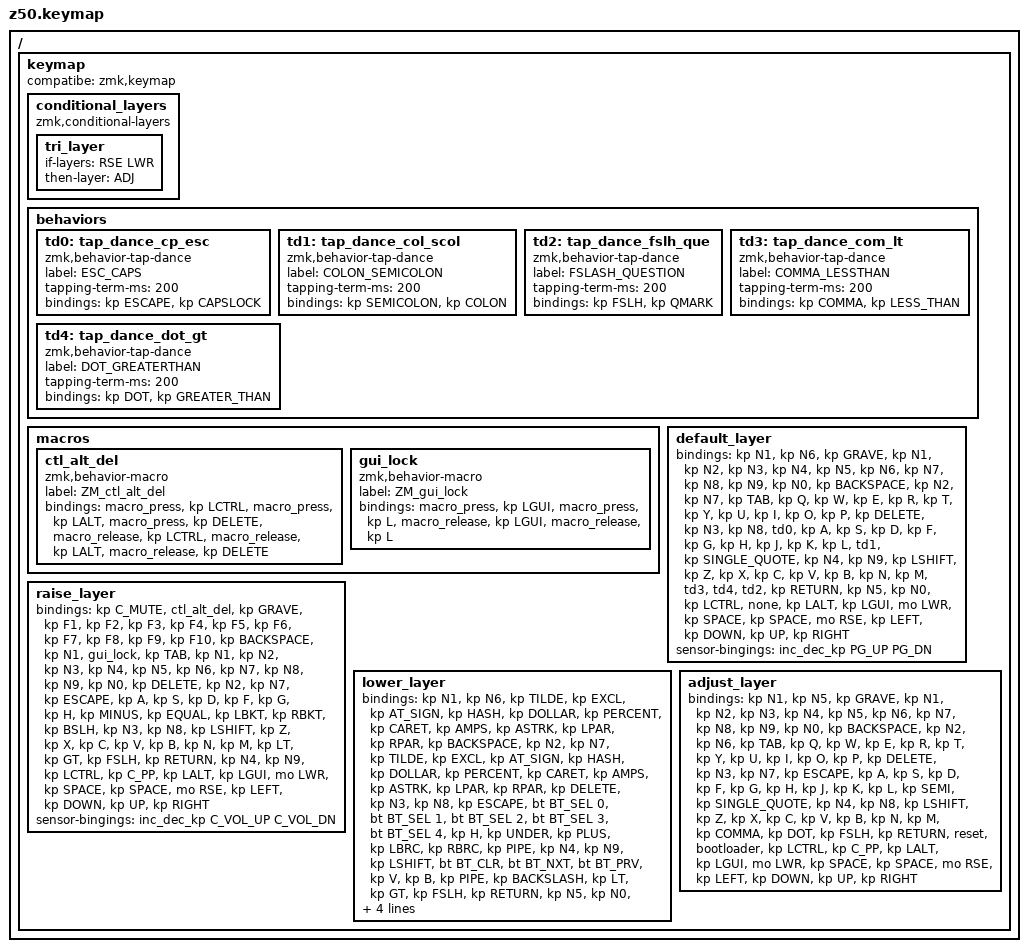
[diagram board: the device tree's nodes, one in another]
#include <behaviors.dtsi>
#include <dt-bindings/zmk/keys.h>
#include <dt-bindings/zmk/bt.h>

#define DEFAULT 0
#define RSE 1
#define LWR 2
#define ADJ 3

/ {
    keymap {
        compatibe = "zmk,keymap";
        // Trigger Adjust layer
        conditional_layers {
            compatible = "zmk,conditional-layers";
            tri_layer {
                if-layers = <RSE LWR>;
                then-layer = <ADJ>;
            };
        };
        // Tap dance behaviors
        behaviors {
            // <ESC, CAPSLOCK>
            td0: tap_dance_cp_esc {
                compatible = "zmk,behavior-tap-dance";
                label = "ESC_CAPS";
                #binding-cells = <0>;
                tapping-term-ms = <200>;
                bindings = <&kp ESCAPE>, <&kp CAPSLOCK>;
            };
            // <SEMICOLON, COLON>
            td1: tap_dance_col_scol {
                compatible = "zmk,behavior-tap-dance";
                label = "COLON_SEMICOLON";
                #binding-cells = <0>;
                tapping-term-ms = <200>;
                bindings = <&kp SEMICOLON>, <&kp COLON>;
            };
            // <FORWARDSLASH, QUESTION>
            td2: tap_dance_fslh_que {
                compatible = "zmk,behavior-tap-dance";
                label = "FSLASH_QUESTION";
                #binding-cells = <0>;
                tapping-term-ms = <200>;
                bindings = <&kp FSLH>, <&kp QMARK>;
            };
            // <COMMA, LESSTHAN>
            td3: tap_dance_com_lt {
                compatible = "zmk,behavior-tap-dance";
                label = "COMMA_LESSTHAN";
                #binding-cells = <0>;
                tapping-term-ms = <200>;
                bindings = <&kp COMMA>, <&kp LESS_THAN>;
            };
            // <PERIOD, GREATERTHAN>
            td4: tap_dance_dot_gt {
                compatible = "zmk,behavior-tap-dance";
                label = "DOT_GREATERTHAN";
                #binding-cells = <0>;
                tapping-term-ms = <200>;
                bindings = <&kp DOT>, <&kp GREATER_THAN>;
            };
        };
        // Macros
        macros {
            ctl_alt_del: ctl_alt_del {
                label = "ZM_ctl_alt_del";
                compatible = "zmk,behavior-macro";
                #binding-cells = <0>;
                bindings = <&macro_press &kp LCTRL>,
                    <&macro_press &kp LALT>,
                    <&macro_press &kp DELETE>,
                    <&macro_release &kp LCTRL>,
                    <&macro_release &kp LALT>,
                    <&macro_release &kp DELETE>;
            };
            gui_lock: gui_lock {
                label = "ZM_gui_lock";
                compatible = "zmk,behavior-macro";
                #binding-cells = <0>;
                bindings = <&macro_press &kp LGUI>,
                    <&macro_press &kp L>,
                    <&macro_release &kp LGUI>,
                    <&macro_release &kp L>;
            };
        };
        // Keymaps by layer
        default_layer {
        // +-----------+----------+---------+-------+-------+-------+-------+-------+-------+-------+-------+-------+-------+---------+
        // |    ENC    |   MC 5   |    `    |   1   |   2   |   3   |   4   |   5   |   6   |   7   |   8   |   9   |   0   |  BKSPC  |   
        // +-----------+----------+---------+-------+-------+-------+-------+-------+-------+-------+-------+-------+-------+---------+
        // |    MC 1   |   MC 6   |   TAB   |   Q   |   W   |   E   |   R   |   T   |   Y   |   U   |   I   |   O   |   P   |   DEL   |
        // +-----------+----------+---------+-------+-------+-------+-------+-------+-------+-------+-------+-------+-------+---------+
        // |    MC 2   |   MC 7   |   ESC   |   A   |   S   |   D   |   F   |   G   |   H   |   J   |   K   |   L   |   ;   |    '    |       
        // +-----------+----------+---------+-------+-------+-------+-------+-------+-------+-------+-------+-------+-------+---------+
        // |    MC 3   |   MC 8   |  SHIFT  |   Z   |   X   |   C   |   V   |   B   |   N   |   M   |   ,   |   .   |   /   |  RETURN |   
        // +-----------+----------+---------+-------+-------+-------+-------+-------+-------+-------+-------+-------+-------+---------+
        // |    MC 4   |   MC 9   |   CTRL  |  FN   | LALT  |  GUI  |  LWR  | SPACE | SPACE |  RSE  | LEFT  | DOWN  |   UP  |  RIGHT  |    
        // +-----------+----------+---------+-------+-------+-------+-------+-------+-------+-------+-------+-------+-------+---------+
            bindings = <
                &kp N1   &kp N6   &kp GRAVE   &kp N1  &kp N2   &kp N3   &kp N4    &kp N5    &kp N6    &kp N7   &kp N8    &kp N9   &kp N0    &kp BACKSPACE 
                &kp N2   &kp N7   &kp TAB     &kp Q   &kp W    &kp E    &kp R     &kp T     &kp Y     &kp U    &kp I     &kp O    &kp P     &kp DELETE
                &kp N3   &kp N8   &td0  &kp A   &kp S    &kp D    &kp F     &kp G     &kp H     &kp J    &kp K     &kp L    &td1  &kp SINGLE_QUOTE
                &kp N4   &kp N9   &kp LSHIFT  &kp Z   &kp X    &kp C    &kp V     &kp B     &kp N     &kp M    &td3 &td4  &td2  &kp RETURN
                &kp N5   &kp N0   &kp LCTRL   &none   &kp LALT &kp LGUI &mo LWR   &kp SPACE &kp SPACE &mo RSE  &kp LEFT  &kp DOWN &kp UP    &kp RIGHT
            >;
            sensor-bingings = <&inc_dec_kp PG_UP PG_DN>;
        };
        
        raise_layer {
        // ENC = C_MUTE
        // MC 5 = CTL+ALT+DEL -- login to windows 
        // MC 6 = LGUI+L -- lock windows desktop
        // +-----------+----------+---------+-------+-------+-------+-------+-------+-------+-------+---------+---------+--------+---------+
        // |    ENC    |   MC 5   |    `    |   F1  |   F2  |   F3  |   F4  |   F5  |   F6  |   F7  |   F8    |   F9    |   F10  |  BKSPC  |   
        // +-----------+----------+---------+-------+-------+-------+-------+-------+-------+-------+---------+---------+--------+---------+
        // |    MC 1   |   MC 6   |   TAB   |   1   |   2   |   3   |   4   |   5   |   6   |   7   |   8     |   9     |    0   |   DEL   |
        // +-----------+----------+---------+-------+-------+-------+-------+-------+-------+-------+---------+---------+--------+---------+
        // |    MC 2   |   MC 7   |   ESC   |   A   |   S   |   D   |   F   |   G   |   H   |   -   |   =     |   [     |   ]    |    \    |       
        // +-----------+----------+---------+-------+-------+-------+-------+-------+-------+-------+---------+---------+--------+---------+
        // |    MC 3   |   MC 8   |  SHIFT  |   Z   |   X   |   C   |   V   |   B   |   N   |   M   |   <     |   >     |   /    |  RETURN |   
        // +-----------+----------+---------+-------+-------+-------+-------+-------+-------+-------+---------+---------+--------+---------+
        // |    MC 4   |   MC 9   |   CTRL  |  FN   | LALT  |  GUI  |  LWR  | SPACE | SPACE |  RSE  | OUT_USB | OUT_BLE |  RALT  | OUT_TOG |    
        // +-----------+----------+---------+-------+-------+-------+-------+-------+-------+-------+---------+---------+--------+---------+
            bindings = <
                &kp C_MUTE   &ctl_alt_del   &kp GRAVE   &kp F1  &kp F2   &kp F3   &kp F4    &kp F5    &kp F6    &kp F7   &kp F8    &kp F9   &kp F10    &kp BACKSPACE 
                &kp N1   &gui_lock   &kp TAB     &kp N1   &kp N2    &kp N3    &kp N4    &kp N5     &kp N6     &kp N7    &kp N8     &kp N9    &kp N0     &kp DELETE
                &kp N2   &kp N7   &kp ESCAPE  &kp A   &kp S    &kp D    &kp F     &kp G     &kp H     &kp MINUS    &kp EQUAL     &kp LBKT    &kp RBKT  &kp BSLH
                &kp N3   &kp N8   &kp LSHIFT  &kp Z   &kp X    &kp C    &kp V     &kp B     &kp N     &kp M    &kp LT &kp GT  &kp FSLH  &kp RETURN
                &kp N4   &kp N9   &kp LCTRL   &kp C_PP  &kp LALT &kp LGUI &mo LWR   &kp SPACE &kp SPACE &mo RSE  &kp LEFT  &kp DOWN &kp UP    &kp RIGHT
            >;
            sensor-bingings = <&inc_dec_kp C_VOL_UP C_VOL_DN>;
        };

        lower_layer {
        // +-----------+----------+---------+--------+--------+--------+-------+-------+-------+-------+-------+-------+-------+---------+
        // |    ENC    |   MC 5   |    ~    |    !   |   @    |    #   |   $   |   %   |   ^   |   &   |   *   |   (   |   )   |  BKSPC  |   
        // +-----------+----------+---------+--------+--------+--------+-------+-------+-------+-------+-------+-------+-------+---------+
        // |    MC 1   |   MC 6   |   TAB   |    !   |   @    |    #   |   $   |   %   |   ^   |   &   |   *   |   (   |   )   |   DEL   |
        // +-----------+----------+---------+--------+--------+--------+-------+-------+-------+-------+-------+-------+-------+---------+
        // |    MC 2   |   MC 7   |   ESC   |  BT 1  |  BT 2  |  BT 3  | BT 4  | BT 5  |   H   |   _   |   +   |   {   |   }   |    |    |       
        // +-----------+----------+---------+--------+--------+--------+-------+-------+-------+-------+-------+-------+-------+---------+
        // |    MC 3   |   MC 8   |  SHIFT  | BT_CLR | BT_NXT | BT_PRV |   V   |   B   |   |   |   \   |   <   |   >   |   /   |  RETURN |   
        // +-----------+----------+---------+--------+--------+--------+-------+-------+-------+-------+-------+-------+-------+---------+
        // |    MC 4   |   MC 9   |   CTRL  |  FN    |  LALT  |  GUI   |  LWR  | SPACE | SPACE |  RSE  | HOME  | PGDWN | PGUP  |   END   |    
        // +-----------+----------+---------+--------+--------+--------+-------+-------+-------+-------+-------+-------+-------+---------+
            bindings = <
                &kp N1   &kp N6   &kp TILDE   &kp EXCL  &kp AT_SIGN   &kp HASH   &kp DOLLAR    &kp PERCENT    &kp CARET    &kp AMPS   &kp ASTRK    &kp LPAR   &kp RPAR    &kp BACKSPACE 
                &kp N2   &kp N7   &kp TILDE   &kp EXCL  &kp AT_SIGN   &kp HASH   &kp DOLLAR    &kp PERCENT    &kp CARET    &kp AMPS   &kp ASTRK    &kp LPAR   &kp RPAR    &kp DELETE 
                &kp N3   &kp N8   &kp ESCAPE  &bt BT_SEL 0 &bt BT_SEL 1  &bt BT_SEL 2  &bt BT_SEL 3  &bt BT_SEL 4  &kp H   &kp UNDER    &kp PLUS     &kp LBRC    &kp RBRC  &kp PIPE 
                &kp N4   &kp N9   &kp LSHIFT  &bt BT_CLR   &bt BT_NXT    &bt BT_PRV  &kp V  &kp B  &kp PIPE  &kp BACKSLASH    &kp LT &kp GT  &kp FSLH  &kp RETURN
                &kp N5   &kp N0   &kp LCTRL   &kp C_PP  &kp LALT &kp LGUI &mo LWR   &kp SPACE &kp SPACE &mo RSE  &kp HOME  &kp PG_DN &kp PG_UP    &kp END
            >;
            sensor-bingdings = <&inc_dec_kp C_VOL_UP C_VOL_DN>;
        };
        adjust_layer {
        // MC 4 = bootloader
        // MC 9 = reset
        // +-----------+----------+---------+-------+-------+-------+-------+-------+-------+-------+-------+-------+-------+---------+
        // |    ENC    |   MC 5   |    `    |   1   |   2   |   3   |   4   |   5   |   6   |   7   |   8   |   9   |   0   |  BKSPC  |   
        // +-----------+----------+---------+-------+-------+-------+-------+-------+-------+-------+-------+-------+-------+---------+
        // |    MC 1   |   MC 6   |   TAB   |   Q   |   W   |   E   |   R   |   T   |   Y   |   U   |   I   |   O   |   P   |   DEL   |
        // +-----------+----------+---------+-------+-------+-------+-------+-------+-------+-------+-------+-------+-------+---------+
        // |    MC 2   |   MC 7   |   ESC   |   A   |   S   |   D   |   F   |   G   |   H   |   J   |   K   |   L   |   ;   |    '    |       
        // +-----------+----------+---------+-------+-------+-------+-------+-------+-------+-------+-------+-------+-------+---------+
        // |    MC 3   |   MC 8   |  SHIFT  |   Z   |   X   |   C   |   V   |   B   |   N   |   M   |   ,   |   .   |   /   |  RETURN |   
        // +-----------+----------+---------+-------+-------+-------+-------+-------+-------+-------+-------+-------+-------+---------+
        // |    MC 4   |   MC 9   |   CTRL  |  FN   | LALT  |  GUI  |  LWR  | SPACE | SPACE |  RSE  | LEFT  | DOWN  |   UP  |  RIGHT  |    
        // +-----------+----------+---------+-------+-------+-------+-------+-------+-------+-------+-------+-------+-------+---------+
            bindings = <
                &kp N1   &kp N5      &kp GRAVE   &kp N1  &kp N2   &kp N3   &kp N4    &kp N5    &kp N6    &kp N7   &kp N8    &kp N9   &kp N0    &kp BACKSPACE 
                &kp N2   &kp N6      &kp TAB     &kp Q   &kp W    &kp E    &kp R     &kp T     &kp Y     &kp U    &kp I     &kp O    &kp P     &kp DELETE
                &kp N3   &kp N7      &kp ESCAPE  &kp A   &kp S    &kp D    &kp F     &kp G     &kp H     &kp J    &kp K     &kp L    &kp SEMI  &kp SINGLE_QUOTE
                &kp N4   &kp N8      &kp LSHIFT  &kp Z   &kp X    &kp C    &kp V     &kp B     &kp N     &kp M    &kp COMMA &kp DOT  &kp FSLH  &kp RETURN
                &reset   &bootloader &kp LCTRL   &kp C_PP  &kp LALT &kp LGUI &mo LWR   &kp SPACE &kp SPACE &mo RSE  &kp LEFT  &kp DOWN &kp UP    &kp RIGHT
            >;
        };
 
    };
};
